VERSION ""

NS_ :

BS_:

BU_: ECU1 ECU2

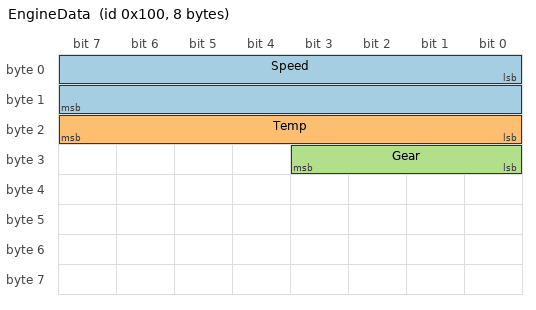
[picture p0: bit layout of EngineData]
BO_ 256 EngineData: 8 ECU1
 SG_ Speed : 0|16@1+ (0.1,0) [0|250] "km/h" ECU2
 SG_ Temp : 16|8@1+ (1,-40) [-40|215] "C" ECU2
 SG_ Gear : 24|4@1+ (1,0) [0|7] "" ECU2

BO_ 512 Status: 8 ECU2
 SG_ Flag : 0|1@1+ (1,0) [0|1] "" ECU1

BA_DEF_ BO_ "GenMsgCycleTime" INT 0 65535;
BA_DEF_DEF_ "GenMsgCycleTime" 0;
BA_ "GenMsgCycleTime" BO_ 256 10;

VAL_ 256 Gear 0 "P" 1 "R" 2 "N" 3 "D" ;
